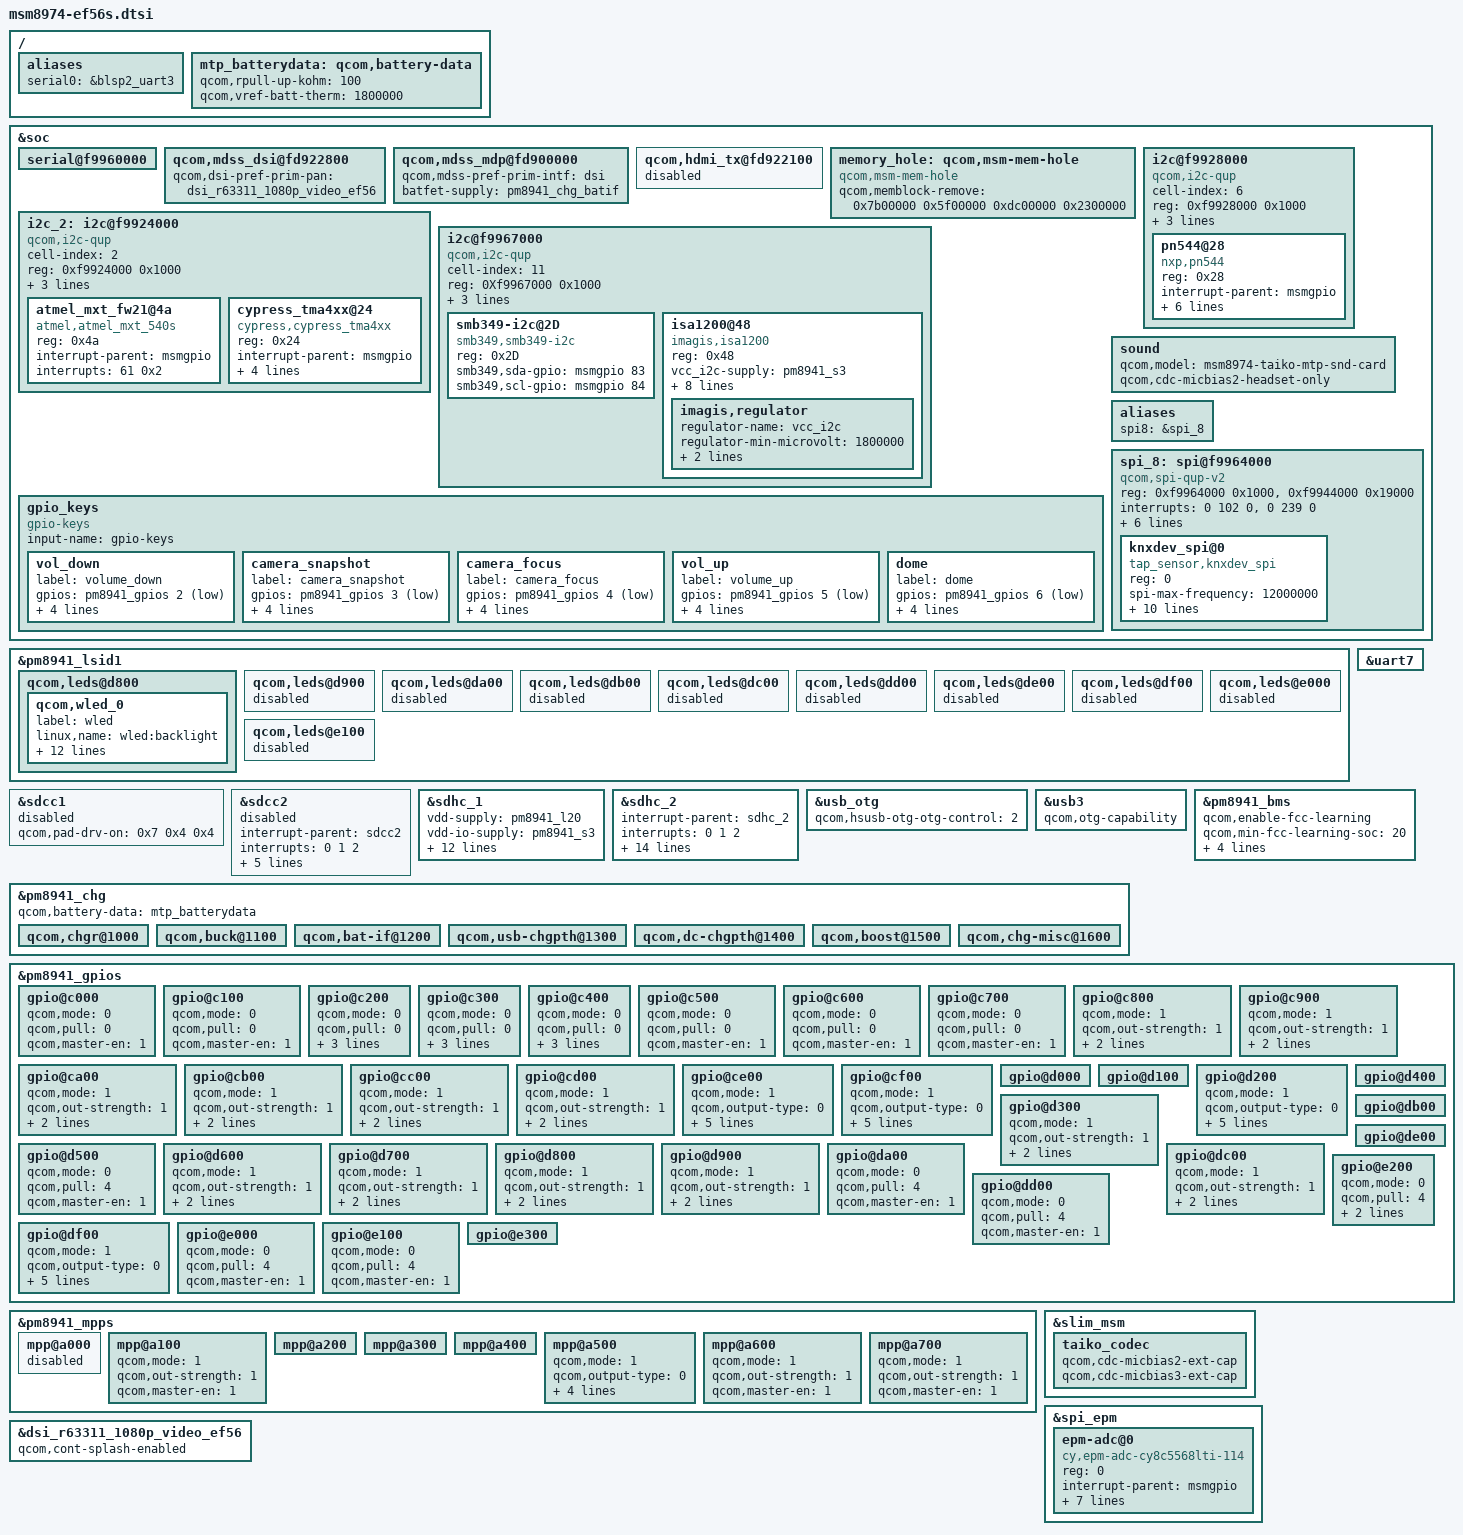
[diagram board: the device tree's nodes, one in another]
/* Copyright (c) 2012-2013, The Linux Foundation. All rights reserved.
 *
 * This program is free software; you can redistribute it and/or modify
 * it under the terms of the GNU General Public License version 2 and
 * only version 2 as published by the Free Software Foundation.
 *
 * This program is distributed in the hope that it will be useful,
 * but WITHOUT ANY WARRANTY; without even the implied warranty of
 * MERCHANTABILITY or FITNESS FOR A PARTICULAR PURPOSE.  See the
 * GNU General Public License for more details.
 */

/include/ "msm8974-camera-sensor-mtp.dtsi"
/include/ "msm8974-leds-ef56s.dtsi"

/ {
	aliases {
		serial0 = &blsp2_uart3;/* blsp1_uart1; */
	};
};

&soc {
	serial@f9960000 {
		status = "ok";
	};

	qcom,mdss_dsi@fd922800 {
		qcom,dsi-pref-prim-pan = <&dsi_r63311_1080p_video_ef56>;
	};

	qcom,mdss_mdp@fd900000 {
		qcom,mdss-pref-prim-intf = "dsi";
		batfet-supply = <&pm8941_chg_batif>;
	};

	qcom,hdmi_tx@fd922100 {
		status = "disabled";
	};

	memory_hole: qcom,msm-mem-hole {
        	compatible = "qcom,msm-mem-hole";
              qcom,memblock-remove = <0x7b00000 0x5f00000
                                          0xdc00000 0x2300000>; /* Address and Size of Hole */

	};

	i2c_2: i2c@f9924000 {
      cell-index = <2>;
      compatible = "qcom,i2c-qup";
      reg = <0xf9924000 0x1000>;
    	#address-cells = <1>;
    	#size-cells = <0>;
      reg-names = "qup_phys_addr";
      interrupts = <0 96 0>;
      interrupt-names = "qup_err_intr";
      qcom,i2c-bus-freq = <1600000>;
      qcom,i2c-src-freq = <50000000>;

      atmel_mxt_fw21@4a {
      compatible = "atmel,atmel_mxt_540s";
			reg = <0x4a>;
			interrupt-parent = <&msmgpio>;
			interrupts = <61 0x2>;
			};
  		cypress_tma4xx@24 {
  			compatible = "cypress,cypress_tma4xx";
  			reg = <0x24>;
  			interrupt-parent = <&msmgpio>;
  			interrupts = <61 0x2>;
  			vcc_i2c-supply = <&pm8941_l10>;
   			cypress,irq-gpio = <&msmgpio 61 0x00>;
    		cypress,i2c-pull-up = <1>;
		};

	};

    i2c@f9967000 {// I2C BUS Slave connected
        cell-index = <11>;
        compatible = "qcom,i2c-qup";
        reg = <0Xf9967000 0x1000>;
        #address-cells = <1>;
        #size-cells = <0>;
        reg-names = "qup_phys_addr";
        interrupts = <0 105 0>;
        interrupt-names = "qup_err_intr";
        qcom,i2c-bus-freq = <100000>;
        qcom,i2c-src-freq = <50000000>;
        smb349-i2c@2D { // Slave driver and slave Address
            compatible = "smb349,smb349-i2c";// Manufacture , model
            reg = <0x2D>; // Slave Address
            smb349,sda-gpio = <&msmgpio 83 0>; /* smb349_I2C_SDA */
            smb349,scl-gpio = <&msmgpio 84 0>; /* smb349_I2C_SCL */
        };
    };


	i2c@f9967000 {
		isa1200@48 {
			status = "okay";
			reg = <0x48>;
			vcc_i2c-supply = <&pm8941_s3>;
			compatible = "imagis,isa1200";
			label = "vibrator";
			imagis,chip-en;
			imagis,need-pwm-clk;
			imagis,ext-clk-en;
			imagis,hap-en-gpio = <&msmgpio 86 0x00>;
			imagis,max-timeout = <15000>;
			imagis,pwm-div = <256>;
			imagis,mode-ctrl = <2>;
			imagis,regulator {
				regulator-name = "vcc_i2c";
				regulator-min-microvolt = <1800000>;
				regulator-max-microvolt = <1800000>;
				regulator-max-microamp = <9360>;
			};
		};
	};

	i2c@f9928000 { /*NFC*/
			cell-index = <6>; 
			compatible = "qcom,i2c-qup"; 
			reg = <0xf9928000 0x1000>; 
			#address-cells = <1>;
			#size-cells = <0>;
			reg-names = "qup_phys_addr"; // Name of QUP_BASE
			interrupts = <0 100 0>;
			interrupt-names = "qup_err_intr"; 
			qcom,i2c-bus-freq = <400000>;
			qcom,i2c-src-freq = <50000000>; 
			pn544@28 {
			compatible = "nxp,pn544";
			reg = <0x28>;
			interrupt-parent = <&msmgpio>;
			interrupts = <59 0x2>;
			nxp,irq-gpio = <&msmgpio 59 0x00>;
			interrupt-names = "irq_gpio";
			nxp,sda-gpio = <&msmgpio 29 0>; /* NFC_I2C_SDA */
			nxp,scl-gpio = <&msmgpio 30 0>; /* NFC_I2C_SCL */
			nxp,ven-gpio = <&msmgpio 50 0>; /* NFC_EXT_EN_MSM */
			nxp,firm-gpio = <&pm8941_gpios  32 0>; /* NFC_F/W_D/L_2 */
		};
	};
	gpio_keys {
		compatible = "gpio-keys";
		input-name = "gpio-keys";

		vol_down {
			label = "volume_down";
			gpios = <&pm8941_gpios 2 0x1>;
			linux,input-type = <1>;
			linux,code = <114>;
			gpio-key,wakeup;
			debounce-interval = <15>;
		};
		
		camera_snapshot {
			label = "camera_snapshot";
			gpios = <&pm8941_gpios 3 0x1>;
			linux,input-type = <1>;
			linux,code = <0x2fe>;
			gpio-key,wakeup;
			debounce-interval = <15>;
		};

		camera_focus {
			label = "camera_focus";
			gpios = <&pm8941_gpios 4 0x1>;
			linux,input-type = <1>;
			linux,code = <0x210>;
			gpio-key,wakeup;
			debounce-interval = <15>;
		};

		vol_up {
			label = "volume_up";
			gpios = <&pm8941_gpios 5 0x1>;
			linux,input-type = <1>;
			linux,code = <115>;
			gpio-key,wakeup;
			debounce-interval = <15>;
		};
		
		dome {
			label = "dome";
			gpios = <&pm8941_gpios 6 0x1>;
			linux,input-type = <1>;
			linux,code = <251>;
			gpio-key,wakeup;
			debounce-interval = <15>;
	};
	};

    /* block for DMB
	spi@f9923000 {
		ethernet-switch@2 {
			compatible = "micrel,ks8851";
			reg = <2>;
			interrupt-parent = <&msmgpio>;
			interrupts = <94 0>;
			spi-max-frequency = <4800000>;
			rst-gpio = <&pm8941_mpps 6 0>;
			vdd-io-supply = <&spi_eth_vreg>;
			vdd-phy-supply = <&spi_eth_vreg>;
		};
	};
    */

	sound {
		qcom,model = "msm8974-taiko-mtp-snd-card";
		qcom,cdc-micbias2-headset-only;
	};

	aliases {
		spi8 = &spi_8;
};

    spi_8: spi@f9964000 { /* BTP_SPI */
		compatible = "qcom,spi-qup-v2";

		reg = <0xf9964000 0x1000>,
			  <0xf9944000 0x19000>;
		reg-names = "spi_physical", "spi_bam_physical"; 
		interrupts = <0 102 0>,  <0 239 0>;
		interrupt-names = "spi_irq", "spi_bam_irq";
		
		spi-max-frequency = <12000000>; 
		#address-cells = <1>;
		#size-cells = <0>;
		
		qcom,use-bam;
		qcom,bam-consumer-pipe-index = <14>;
		qcom,bam-producer-pipe-index = <15>;
		qcom,ver-reg-exists;
		qcom,master-id = <84>;

		knxdev_spi@0{
		  compatible = "tap_sensor,knxdev_spi";
		  reg=<0>;
		  spi-max-frequency = <12000000>;
		  #spi-cpol;
		  #spi-cpha; /* MODE 0 */
		  #spi-cs-high;
		  interrupt-parent = <&msmgpio>;
		  interrupts = <77 0>;
		  tap_sensor,irq-gpio = <&msmgpio 77 0x00>;
		  #interrupt-names = "irq_gpio";
		  tap_sensor,gpios = <&msmgpio 48 0>, /* BTP CLK  */
		   <&msmgpio 46 0>, /* BTP MISO */
		   <&msmgpio 45 0>; /* BTP MOSI */
		   tap_sensor,cs-gpios = <&msmgpio 47 0>; /* BTP CS */
		  
		};
	};
};

&pm8941_lsid1 {
	qcom,leds@d800 {
		status = "okay";
		qcom,wled_0 {
			label = "wled";
			linux,name = "wled:backlight";
			linux,default-trigger = "bkl-trigger";
			qcom,cs-out-en;
			qcom,op-fdbck = <1>;
			qcom,default-state = "on";
			qcom,max-current = <25>;
			qcom,ctrl-delay-us = <0>;
			qcom,boost-curr-lim = <5>;
			qcom,cp-sel = <0>;
			qcom,switch-freq = <11>;
			qcom,ovp-val = <2>;
			qcom,num-strings = <3>;
			qcom,id = <0>;
		};
	};

	qcom,leds@d900 {
		status = "disabled";
	};

	qcom,leds@da00 {
		status = "disabled";
	};

	qcom,leds@db00 {
		status = "disabled";
	};

	qcom,leds@dc00 {
		status = "disabled";
	};

	qcom,leds@dd00 {
		status = "disabled";
	};

	qcom,leds@de00 {
		status = "disabled";
	};

	qcom,leds@df00 {
		status = "disabled";
	};

	qcom,leds@e000 {
		status = "disabled";
	};

	qcom,leds@e100 {
		status = "disabled";
	};
};

&sdcc1 {
       status = "disabled";
};

&sdcc2 {
	#address-cells = <0>;
	interrupt-parent = <&sdcc2>;
	interrupts = <0 1 2>;
	#interrupt-cells = <1>;
	interrupt-map-mask = <0xffffffff>;
	interrupt-map = <0 &intc 0 125 0
			1 &intc 0 220 0
			2 &msmgpio 62 0x3>;
	interrupt-names = "core_irq", "bam_irq", "status_irq";
	cd-gpios = <&msmgpio 62 0x1>;
	status = "disabled";
};

&sdhc_1 {
	vdd-supply = <&pm8941_l20>;
	vdd-io-supply = <&pm8941_s3>;

	qcom,vdd-always-on;
	qcom,vdd-lpm-sup;
	qcom,vdd-voltage-level = <2950000 2950000>;
	qcom,vdd-current-level = <800 500000>;

	qcom,vdd-io-always-on;
	qcom,vdd-io-voltage-level = <1800000 1800000>;
	qcom,vdd-io-current-level = <250 154000>;

	qcom,pad-pull-on = <0x0 0x3 0x3>; /* no-pull, pull-up, pull-up */
	qcom,pad-pull-off = <0x0 0x3 0x3>; /* no-pull, pull-up, pull-up */
	qcom,pad-drv-on = <0x4 0x4 0x4>; /* 10mA, 10mA, 10mA */
	qcom,pad-drv-off = <0x0 0x0 0x0>; /* 2mA, 2mA, 2mA */

	qcom,nonremovable;
	status = "ok";
};

&sdhc_2 {
	#address-cells = <0>;
	interrupt-parent = <&sdhc_2>;
	interrupts = <0 1 2>;
	#interrupt-cells = <1>;
	interrupt-map-mask = <0xffffffff>;
	interrupt-map = <0 &intc 0 125 0
			1 &intc 0 221 0
			2 &msmgpio 62 0x3>;
	interrupt-names = "hc_irq", "pwr_irq", "status_irq";
	cd-gpios = <&msmgpio 62 0x1>;

	vdd-supply = <&pm8941_l21>;
	vdd-io-supply = <&pm8941_l13>;

	qcom,vdd-voltage-level = <2950000 2950000>;
	qcom,vdd-current-level = <9000 800000>;

	qcom,vdd-io-voltage-level = <1800000 2950000>;
	qcom,vdd-io-current-level = <6 22000>;

	qcom,pad-pull-on = <0x0 0x3 0x3>; /* no-pull, pull-up, pull-up */
	qcom,pad-pull-off = <0x0 0x3 0x3>; /* no-pull, pull-up, pull-up */
	qcom,pad-drv-on = <0x4 0x4 0x4>; /* 10mA, 10mA, 10mA */
	qcom,pad-drv-off = <0x0 0x0 0x0>; /* 2mA, 2mA, 2mA */
	status = "ok";
};

/* Drive strength recommendations for clock line from hardware team is 10 mA.
 * But since the driver has been been using the below values from the start
 * without any problems, continue to use those.
 */
&sdcc1 {
	qcom,pad-drv-on = <0x7 0x4 0x4>; /* 16mA, 10mA, 10mA */
};

&sdcc2 {
	qcom,pad-drv-on = <0x7 0x4 0x4>; /* 16mA, 10mA, 10mA */
};

&sdhc_1 {
	qcom,pad-drv-on = <0x7 0x4 0x4>; /* 16mA, 10mA, 10mA */
};

&sdhc_2 {
	qcom,pad-drv-on = <0x7 0x4 0x4>; /* 16mA, 10mA, 10mA */
};

&usb_otg {
	qcom,hsusb-otg-otg-control = <2>;
};

&uart7 {
	status = "ok";
};

&usb3 {
	qcom,otg-capability;
};

/ {
	mtp_batterydata: qcom,battery-data {
		qcom,rpull-up-kohm = <100>;
		qcom,vref-batt-therm = <1800000>;

		/include/ "batterydata-palladium.dtsi"
		/include/ "batterydata-mtp-3000mah.dtsi"
	};
};

&pm8941_bms {
	qcom,enable-fcc-learning;
	qcom,min-fcc-learning-soc = <20>;
	qcom,min-fcc-ocv-pc = <30>;
	qcom,min-fcc-learning-samples = <5>;
	qcom,fcc-resolution = <10>;
	status = "ok";
	qcom,battery-data = <&mtp_batterydata>;
};

&pm8941_chg {
	status = "ok";
	qcom,battery-data = <&mtp_batterydata>;

	qcom,chgr@1000 {
		status = "ok";
	};

	qcom,buck@1100 {
		status = "ok";
	};

	qcom,bat-if@1200 {
		status = "ok";
	};

	qcom,usb-chgpth@1300 {
		status = "ok";
	};

	qcom,dc-chgpth@1400 {
		status = "ok";
	};

	qcom,boost@1500 {
		status = "ok";
	};

	qcom,chg-misc@1600 {
		status = "ok";
	};
};

&pm8941_gpios {
	gpio@c000 { /* GPIO 1 */
		qcom,mode = <0>;        /* QPNP_PIN_MODE_DIG_IN */
		qcom,pull = <0>;        /* QPNP_PIN_PULL_UP_30  */
		qcom,master-en = <1>;
	};

	gpio@c100 { /* GPIO 2 */
		qcom,mode = <0>;        /* QPNP_PIN_MODE_DIG_IN */
		qcom,pull = <0>;        /* QPNP_PIN_PULL_UP_30  */
		qcom,master-en = <1>;
	};

	gpio@c200 { /* GPIO 3 */
		qcom,mode = <0>;        /* QPNP_PIN_MODE_DIG_IN */
		qcom,pull = <0>;        /* QPNP_PIN_PULL_UP_30  */
		qcom,vin-sel = <2>;
		qcom,src-sel = <0>;	/* QPNP_PIN_SEL_FUNC_CONSTANT */
		qcom,master-en = <1>;
	};

	gpio@c300 { /* GPIO 4 */
		qcom,mode = <0>;        /* QPNP_PIN_MODE_DIG_IN */
		qcom,pull = <0>;        /* QPNP_PIN_PULL_UP_30  */
		qcom,vin-sel = <2>;     /* QPNP_PIN_VIN2  */
		qcom,src-sel = <0>;	/* QPNP_PIN_SEL_FUNC_CONSTANT */
		qcom,master-en = <1>;
	};

	gpio@c400 { /* GPIO 5 */
		qcom,mode = <0>;        /* QPNP_PIN_MODE_DIG_IN */
		qcom,pull = <0>;        /* QPNP_PIN_PULL_UP_30  */
		qcom,vin-sel = <2>;     /* QPNP_PIN_VIN2  */
		qcom,src-sel = <0>;	/* QPNP_PIN_SEL_FUNC_CONSTANT */
		qcom,master-en = <1>;
	};

	gpio@c500 { /* GPIO 6 */
		qcom,mode = <0>;        /* QPNP_PIN_MODE_DIG_IN */
		qcom,pull = <0>;        /* QPNP_PIN_PULL_UP_30  */
		qcom,master-en = <1>;
	};

	gpio@c600 { /* GPIO 7 */
		qcom,mode = <0>;        /* QPNP_PIN_MODE_DIG_IN */
		qcom,pull = <0>;        /* QPNP_PIN_PULL_UP_30  */
		qcom,master-en = <1>;
	};

	gpio@c700 { /* GPIO 8 */
		qcom,mode = <0>;        /* QPNP_PIN_MODE_DIG_IN */
		qcom,pull = <0>;        /* QPNP_PIN_PULL_UP_30  */
		qcom,master-en = <1>;
	};

	gpio@c800 { /* GPIO 9 */
		qcom,mode = <1>;          /* QPNP_PIN_MODE_DIG_OUT */
		qcom,out-strength = <1>;  /* QPNP_PIN_OUT_STRENGTH_LOW */
		qcom,src-sel = <2>;       /* QPNP_PIN_SEL_FUNC_1  */
		qcom,master-en = <1>;
	};

	gpio@c900 { /* GPIO 10 */
		qcom,mode = <1>;          /* QPNP_PIN_MODE_DIG_OUT */
		qcom,out-strength = <1>;  /* QPNP_PIN_OUT_STRENGTH_LOW */
		qcom,src-sel = <2>;       /* QPNP_PIN_SEL_FUNC_1  */
		qcom,master-en = <1>;
	};

	gpio@ca00 { /* GPIO 11 */
		qcom,mode = <1>;          /* QPNP_PIN_MODE_DIG_OUT */
		qcom,out-strength = <1>;  /* QPNP_PIN_OUT_STRENGTH_LOW */
		qcom,src-sel = <2>;       /* QPNP_PIN_SEL_FUNC_1  */
		qcom,master-en = <1>;
	};

	gpio@cb00 { /* GPIO 12 */
		qcom,mode = <1>;          /* QPNP_PIN_MODE_DIG_OUT */
		qcom,out-strength = <1>;  /* QPNP_PIN_OUT_STRENGTH_LOW */
		qcom,src-sel = <2>;       /* QPNP_PIN_SEL_FUNC_1  */
		qcom,master-en = <1>;
	};

	gpio@cc00 { /* GPIO 13 */
		qcom,mode = <1>;          /* QPNP_PIN_MODE_DIG_OUT */
		qcom,out-strength = <1>;  /* QPNP_PIN_OUT_STRENGTH_LOW */
		qcom,src-sel = <2>;       /* QPNP_PIN_SEL_FUNC_1  */
		qcom,master-en = <1>;
	};

	gpio@cd00 { /* GPIO 14 */
		qcom,mode = <1>;          /* QPNP_PIN_MODE_DIG_OUT */
		qcom,out-strength = <1>;  /* QPNP_PIN_OUT_STRENGTH_LOW */
		qcom,src-sel = <2>;       /* QPNP_PIN_SEL_FUNC_1  */
		qcom,master-en = <1>;
	};

	gpio@ce00 { /* GPIO 15 */
		qcom,mode = <1>;
		qcom,output-type = <0>;
		qcom,pull = <5>;
		qcom,vin-sel = <2>;
		qcom,out-strength = <1>;
		qcom,src-sel = <2>;
		qcom,master-en = <1>;
	};

	gpio@cf00 { /* GPIO 16 */
		qcom,mode = <1>;
		qcom,output-type = <0>;
		qcom,pull = <5>;
		qcom,vin-sel = <2>;
		qcom,out-strength = <3>;
		qcom,src-sel = <3>;       /* QPNP_PIN_SEL_FUNC_2  */
		qcom,master-en = <1>;
	};

	gpio@d000 { /* GPIO 17 */
	};

	gpio@d100 { /* GPIO 18 */
	};

	gpio@d200 { /* GPIO 19 */
		qcom,mode = <1>;		/* QPNP_PIN_MODE_DIG_OUT */
		qcom,output-type = <0>;		/* QPNP_PIN_OUT_BUF_CMOS */
		qcom,pull = <5>;		/* QPNP_PIN_PULL_NO */
		qcom,vin-sel = <2>;		/* QPNP_PIN_VIN2 */
		qcom,out-strength = <1>;	/* QPNP_PIN_OUT_STRENGTH_LOW */
		qcom,src-sel = <0>;		/* QPNP_PIN_SEL_FUNC_CONSTANT */
		qcom,master-en = <1>;
	};

	gpio@d300 { /* GPIO 20 */
		qcom,mode = <1>;          /* QPNP_PIN_MODE_DIG_OUT */
		qcom,out-strength = <1>;  /* QPNP_PIN_OUT_STRENGTH_LOW */
		qcom,src-sel = <2>;       /* QPNP_PIN_SEL_FUNC_1  */
		qcom,master-en = <1>;
	};

	gpio@d400 { /* GPIO 21 */
	};

	gpio@d500 { /* GPIO 22 */
		qcom,mode = <0>;        /* QPNP_PIN_MODE_DIG_IN */
		qcom,pull = <4>;	/* QPNP_PIN_PULL_DN */
		qcom,master-en = <1>;
	};

	gpio@d600 { /* GPIO 23 */
		qcom,mode = <1>;          /* QPNP_PIN_MODE_DIG_OUT */
		qcom,out-strength = <1>;  /* QPNP_PIN_OUT_STRENGTH_LOW */
		qcom,src-sel = <2>;       /* QPNP_PIN_SEL_FUNC_1  */
		qcom,master-en = <1>;
	};

	gpio@d700 { /* GPIO 24 */
		qcom,mode = <1>;          /* QPNP_PIN_MODE_DIG_OUT */
		qcom,out-strength = <1>;  /* QPNP_PIN_OUT_STRENGTH_LOW */
		qcom,src-sel = <2>;       /* QPNP_PIN_SEL_FUNC_1  */
		qcom,master-en = <1>;
	};

	gpio@d800 { /* GPIO 25 */
		qcom,mode = <1>;          /* QPNP_PIN_MODE_DIG_OUT */
		qcom,out-strength = <1>;  /* QPNP_PIN_OUT_STRENGTH_LOW */
		qcom,src-sel = <2>;       /* QPNP_PIN_SEL_FUNC_1  */
		qcom,master-en = <1>;
	};

	gpio@d900 { /* GPIO 26 */
		qcom,mode = <1>;          /* QPNP_PIN_MODE_DIG_OUT */
		qcom,out-strength = <1>;  /* QPNP_PIN_OUT_STRENGTH_LOW */
		qcom,src-sel = <2>;       /* QPNP_PIN_SEL_FUNC_1  */
		qcom,master-en = <1>;
	};

	gpio@da00 { /* GPIO 27 */
		qcom,mode = <0>;        /* QPNP_PIN_MODE_DIG_IN */
		qcom,pull = <4>;	/* QPNP_PIN_PULL_DN */
		qcom,master-en = <1>;
	};

	gpio@db00 { /* GPIO 28 */
	};

	gpio@dc00 { /* GPIO 29 */
		qcom,mode = <1>;          /* QPNP_PIN_MODE_DIG_OUT */
		qcom,out-strength = <1>;  /* QPNP_PIN_OUT_STRENGTH_LOW */
		qcom,src-sel = <2>;       /* QPNP_PIN_SEL_FUNC_1  */
		qcom,master-en = <1>;
	};

	gpio@dd00 { /* GPIO 30 */
		qcom,mode = <0>;        /* QPNP_PIN_MODE_DIG_IN */
		qcom,pull = <4>;	/* QPNP_PIN_PULL_DN */
		qcom,master-en = <1>;
	};

	gpio@de00 { /* GPIO 31 */
	};

	gpio@df00 { /* GPIO 32 */
		qcom,mode = <1>; /* qcom,mode = <0>;  */      /* QPNP_PIN_MODE_DIG_IN */
		qcom,output-type = <0>;
		qcom,pull = <4>;
		qcom,vin-sel = <2>;
		qcom,out-strength = <1>;
		qcom,src-sel = <2>;
		qcom,master-en = <1>;
	};

	gpio@e000 { /* GPIO 33 */
		qcom,mode = <0>;        /* QPNP_PIN_MODE_DIG_IN */
		qcom,pull = <4>;	/* QPNP_PIN_PULL_DN */
		qcom,master-en = <1>;
	};

	gpio@e100 { /* GPIO 34 */
		qcom,mode = <0>;        /* QPNP_PIN_MODE_DIG_IN */
		qcom,pull = <4>;	/* QPNP_PIN_PULL_DN */
		qcom,master-en = <1>;
	};

	gpio@e200 { /* GPIO 35 */
		qcom,mode = <0>;        /* QPNP_PIN_MODE_DIG_IN */
		qcom,pull = <4>;	/* QPNP_PIN_PULL_DN */
		qcom,master-en = <1>;
		qcom,vin-sel = <2>; /* select 1.8 V source */
	};

	gpio@e300 { /* GPIO 36 */
	};
};

&pm8941_mpps {

	mpp@a000 { /* MPP 1 */
		status = "disabled";
	};

	mpp@a100 { /* MPP 2 */
		qcom,mode = <1>;          /* QPNP_PIN_MODE_DIG_OUT */
		qcom,out-strength = <1>;  /* QPNP_PIN_OUT_STRENGTH_LOW */
		qcom,master-en = <1>;
	};

	mpp@a200 { /* MPP 3 */
	};

	mpp@a300 { /* MPP 4 */
	};

	mpp@a400 { /* MPP 5 */
	};

	mpp@a500 { /* MPP 6 */
		/* SPI_ETH_RST config */
		qcom,mode = <1>; /* DIG_OUT */
		qcom,output-type = <0>; /* CMOS */
		qcom,vin-sel = <2>; /* PM8941_S3 1.8V > 1.6V */
		qcom,src-sel = <0>; /* CONSTANT */
		qcom,out-strength = <1>;  /* QPNP_PIN_OUT_STRENGTH_LOW */
		qcom,master-en = <1>; /* ENABLE MPP */
	};

	mpp@a600 { /* MPP 7 */
		qcom,mode = <1>;          /* QPNP_PIN_MODE_DIG_OUT */
		qcom,out-strength = <1>;  /* QPNP_PIN_OUT_STRENGTH_LOW */
		qcom,master-en = <1>;
	};

	mpp@a700 { /* MPP 8 */
		qcom,mode = <1>;          /* QPNP_PIN_MODE_DIG_OUT */
		qcom,out-strength = <1>;  /* QPNP_PIN_OUT_STRENGTH_LOW */
		qcom,master-en = <1>;
	};
};

&slim_msm {
	taiko_codec {
		qcom,cdc-micbias2-ext-cap;
		qcom,cdc-micbias3-ext-cap;
	};
};

&spi_epm {
	epm-adc@0 {
		compatible = "cy,epm-adc-cy8c5568lti-114";
		reg = <0>;
		interrupt-parent = <&msmgpio>;
		spi-max-frequency = <960000>;
		qcom,channels = <31>;
		qcom,gain = <100 100 100 50 100 100 1 100 1 50
				1 100 1 100 50 50 50 50 50 50
				100 50 100 50 50 50 50 50 50 50
				50>;
		qcom,rsense = <2 2 2 200 20 2 1 2 1 30
				1 10 1 30 50 30 500 30 100 30
				100 500 20 200 1000 20 1000 1000 70 200
				50>;
		qcom,channel-type = <0x1540>;
	};
};

&dsi_r63311_1080p_video_ef56 {
       qcom,cont-splash-enabled;
};
